# STM32WBA54 register map
File version: 1.0
CPU: CM33 r0p1, little endian, MPU, FPU, 4 interrupt priority bits
Registers are 32-bit, read-write, reset 0x0 unless marked. A register's access mark holds for its fields unless they carry their own. Offsets are from the block's base; [hi:lo] are bit positions.

## GTZC1_TZSC
Base 0x40032400
Same registers: SEC_GTZC1_TZSC 0x50032400
0x00 GTZC1_TZSC_CR — GTZC1 TZSC control register
  [0] LCK — lock the configuration of GTZC1_TZSC_SECCFGRn and GTZC1_TZSC_PRIVCFGRn registers until next reset This bit is cleared by default and once set, it can not be reset until system reset.
    0=configuration of all GTZC1_TZSC_SECCFGRn and GTZC1_TZSC_PRIVCFGRn registers not locked; 1=configuration of all GTZC1_TZSC_SECCFGRn and GTZC1_TZSC_PRIVCFGRn registers locked
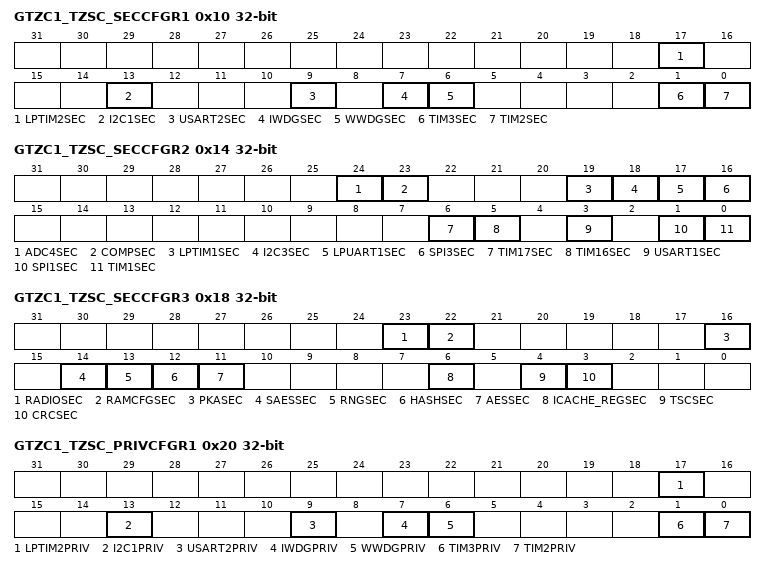
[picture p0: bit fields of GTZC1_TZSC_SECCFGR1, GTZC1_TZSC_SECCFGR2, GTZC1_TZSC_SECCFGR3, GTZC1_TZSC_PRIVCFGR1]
0x10 GTZC1_TZSC_SECCFGR1 — GTZC1 TZSC secure configuration register 1
  [all] fields
    0=non-secure; 1=secure
  [17] LPTIM2SEC — secure access mode for LPTIM2
  [13] I2C1SEC — secure access mode for I2C1
  [9] USART2SEC — secure access mode for USART2
  [7] IWDGSEC — secure access mode for IWDG
  [6] WWDGSEC — secure access mode for WWDG
  [1] TIM3SEC — secure access mode for TIM3
  [0] TIM2SEC — secure access mode for TIM2
0x14 GTZC1_TZSC_SECCFGR2 — GTZC1 TZSC secure configuration register 2
  [all] fields
    0=non-secure; 1=secure
  [24] ADC4SEC — secure access mode for ADC4
  [23] COMPSEC — secure access mode for COMP Note that bit 23 is reserved on sales type STM32WBA52.
  [19] LPTIM1SEC — secure access mode for LPTIM1
  [18] I2C3SEC — secure access mode for I2C3
  [17] LPUART1SEC — secure access mode for LPUART1
  [16] SPI3SEC — secure access mode for SPI3
  [6] TIM17SEC — secure access mode for TIM17
  [5] TIM16SEC — secure access mode for TIM16
  [3] USART1SEC — secure access mode for USART1
  [1] SPI1SEC — secure access mode for SPI1
  [0] TIM1SEC — secure access mode for TIM1
0x18 GTZC1_TZSC_SECCFGR3 — GTZC1 TZSC secure configuration register 3
  [all] fields
    0=non-secure; 1=secure
  [23] RADIOSEC — secure access mode for 2.4 GHz RADIO
  [22] RAMCFGSEC — secure access mode for RAMCFG
  [16] PKASEC — secure access mode for PKA
  [14] SAESSEC — secure access mode for SAES
  [13] RNGSEC — secure access mode for RNG
  [12] HASHSEC — secure access mode for HASH
  [11] AESSEC — secure access mode for AES
  [6] ICACHE_REGSEC — secure access mode for ICACHE registers
  [4] TSCSEC — secure access mode for TSC
  [3] CRCSEC — secure access mode for CRC
0x20 GTZC1_TZSC_PRIVCFGR1 — GTZC1 TZSC privilege configuration register 1
  [all] fields
    0=unprivileged; 1=privileged
  [17] LPTIM2PRIV — privileged access mode for LPTIM2
  [13] I2C1PRIV — privileged access mode for I2C1
  [9] USART2PRIV — privileged access mode for USART2
  [7] IWDGPRIV — privileged access mode for IWDG
  [6] WWDGPRIV — privileged access mode for WWDG
  [1] TIM3PRIV — privileged access mode for TIM3
  [0] TIM2PRIV — privileged access mode for TIM2
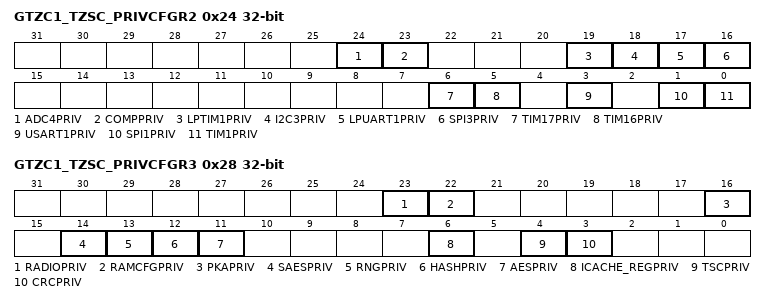
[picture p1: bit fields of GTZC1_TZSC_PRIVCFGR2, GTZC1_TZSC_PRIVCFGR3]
0x24 GTZC1_TZSC_PRIVCFGR2 — GTZC1 TZSC privilege configuration register 2
  [all] fields
    0=unprivileged; 1=privileged
  [24] ADC4PRIV — privileged access mode for ADC4
  [23] COMPPRIV — privileged access mode for COMP Note that bit 23 is reserved on sales type STM32WBA52.
  [19] LPTIM1PRIV — privileged access mode for LPTIM1
  [18] I2C3PRIV — privileged access mode for I2C3
  [17] LPUART1PRIV — privileged access mode for LPUART1
  [16] SPI3PRIV — privileged access mode for SPI3
  [6] TIM17PRIV — privileged access mode for TIM17
  [5] TIM16PRIV — privileged access mode for TIM16
  [3] USART1PRIV — privileged access mode for USART1
  [1] SPI1PRIV — privileged access mode for SPI1PRIV
  [0] TIM1PRIV — privileged access mode for TIM1
0x28 GTZC1_TZSC_PRIVCFGR3 — GTZC1 TZSC privilege configuration register 3
  [all] fields
    0=unprivileged; 1=privileged
  [23] RADIOPRIV — privileged access mode for 2.4 GHz RADIO
  [22] RAMCFGPRIV — privileged access mode for RAMCFG
  [16] PKAPRIV — privileged access mode for PKA
  [14] SAESPRIV — privileged access mode for SAES
  [13] RNGPRIV — privileged access mode for RNG
  [12] HASHPRIV — privileged access mode for HASH
  [11] AESPRIV — privileged access mode for AES
  [6] ICACHE_REGPRIV — privileged access mode for ICACHE registers
  [4] TSCPRIV — privileged access mode for TSC
  [3] CRCPRIV — privileged access mode for CRC
